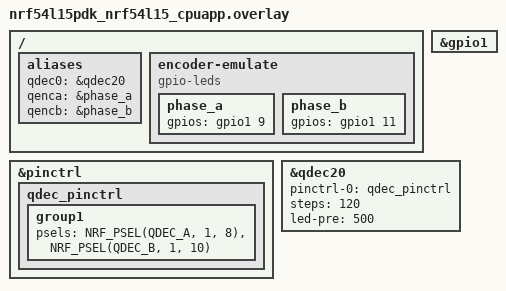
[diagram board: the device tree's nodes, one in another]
/*
 * Copyright 2024 Nordic Semiconductor ASA
 * SPDX-License-Identifier: Apache-2.0
 */

/ {
	aliases {
		qdec0 = &qdec20;
		qenca = &phase_a;
		qencb = &phase_b;
	};

	encoder-emulate {
		compatible = "gpio-leds";
		phase_a: phase_a {
			gpios = <&gpio1 9 GPIO_ACTIVE_HIGH>;
		};
		phase_b: phase_b {
			gpios = <&gpio1 11 GPIO_ACTIVE_HIGH>;
		};
	};
};

&pinctrl {
	qdec_pinctrl: qdec_pinctrl {
		group1 {
			psels = <NRF_PSEL(QDEC_A, 1, 8)>,
				<NRF_PSEL(QDEC_B, 1, 10)>;
		};
	};
};

&gpio1 {
	status = "okay";
};

&qdec20 {
	status = "okay";
	pinctrl-0 = <&qdec_pinctrl>;
	pinctrl-names = "default";
	steps = <120>;
	led-pre = <500>;
};
